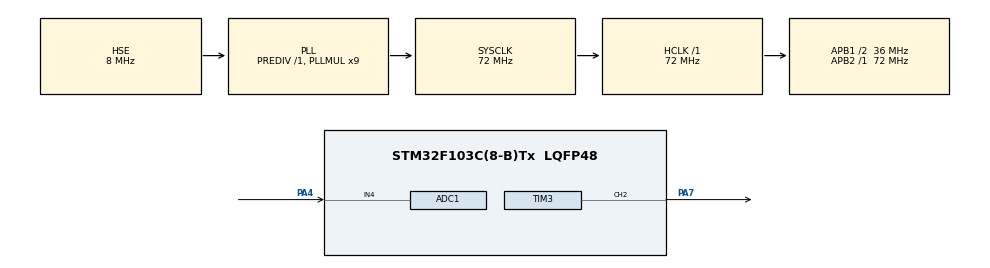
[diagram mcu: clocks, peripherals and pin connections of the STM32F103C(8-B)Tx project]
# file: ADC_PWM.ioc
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ADC1.Channel-0\#ChannelRegularConversion=ADC_CHANNEL_4
ADC1.DiscontinuousConvMode=DISABLE
ADC1.NbrOfConversion=1
ADC1.NbrOfConversionFlag=1
ADC1.Rank-0\#ChannelRegularConversion=1
ADC1.SamplingTime-0\#ChannelRegularConversion=ADC_SAMPLETIME_7CYCLES_5
ADC1.master=1
Mcu.Family=STM32F1
Mcu.Name=STM32F103C(8-B)Tx
Mcu.Package=LQFP48
NVIC.PriorityGroup=NVIC_PRIORITYGROUP_4
PA4.Signal=ADCx_IN4
PA7.Signal=S_TIM3_CH2
PD0-OSC_IN.Mode=HSE-External-Oscillator
PD0-OSC_IN.Signal=RCC_OSC_IN
PD1-OSC_OUT.Mode=HSE-External-Oscillator
PD1-OSC_OUT.Signal=RCC_OSC_OUT
ProjectManager.HeapSize=0x200
ProjectManager.StackSize=0x400
ProjectManager.TargetToolchain=Makefile
RCC.ADCPresc=RCC_ADCPCLK2_DIV6
RCC.AHBFreq_Value=72000000
RCC.APB1CLKDivider=RCC_HCLK_DIV2
RCC.APB1Freq_Value=36000000
RCC.APB1TimFreq_Value=72000000
RCC.APB2Freq_Value=72000000
RCC.APB2TimFreq_Value=72000000
RCC.HCLKFreq_Value=72000000
RCC.PLLMUL=RCC_PLL_MUL9
RCC.PLLSourceVirtual=RCC_PLLSOURCE_HSE
RCC.SYSCLKFreq_VALUE=72000000
RCC.SYSCLKSource=RCC_SYSCLKSOURCE_PLLCLK
RCC.USBFreq_Value=72000000
SH.ADCx_IN4.0=ADC1_IN4,IN4
SH.S_TIM3_CH2.0=TIM3_CH2,PWM Generation2 CH2
TIM3.Channel-PWM\ Generation2\ CH2=TIM_CHANNEL_2
TIM3.Period=2000-1
TIM3.Prescaler=720-1
VP_SYS_VS_ND.Mode=No_Debug
board=custom

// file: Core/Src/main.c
/* USER CODE BEGIN Header */
/**
  ******************************************************************************
  * @file           : main.c
  * @brief          : Main program body
  ******************************************************************************
  * @attention
  *
  * Copyright (c) 2026 STMicroelectronics.
  * All rights reserved.
  *
  * This software is licensed under terms that can be found in the LICENSE file
  * in the root directory of this software component.
  * If no LICENSE file comes with this software, it is provided AS-IS.
  *
  ******************************************************************************
  */
/* USER CODE END Header */
#include "main.h"
#include "adc.h"
#include "tim.h"
#include "gpio.h"

void SystemClock_Config(void);

/* USER CODE BEGIN 0 */
uint16_t adc_x;
uint16_t ccr_val;
/* USER CODE END 0 */

int main(void)
{

  /* MCU Configuration--------------------------------------------------------*/

  /* Reset of all peripherals, Initializes the Flash interface and the Systick. */
  HAL_Init();

  /* Configure the system clock */
  SystemClock_Config();

  /* Initialize all configured peripherals */
  MX_GPIO_Init();
  MX_ADC1_Init();
  MX_TIM3_Init();
  /* USER CODE BEGIN 2 */
HAL_TIM_PWM_Start(&htim3,TIM_CHANNEL_2);
  /* USER CODE END 2 */

  /* Infinite loop */
  while (1)
  {

    /* USER CODE BEGIN 3 */
    if(HAL_ADC_Start(&hadc1)==HAL_OK)
    {
      if(HAL_ADC_PollForConversion(&hadc1,1)==HAL_OK)
      {
        adc_x=HAL_ADC_GetValue(&hadc1);
        ccr_val=50U+(uint16_t)((200UL*adc_x)/4095U);
        __HAL_TIM_SET_COMPARE(&htim3,TIM_CHANNEL_2,ccr_val);
      }
      HAL_ADC_Stop(&hadc1);
    }
    HAL_Delay(20);
  }
  /* USER CODE END 3 */
}

void SystemClock_Config(void)
{
  RCC_OscInitTypeDef RCC_OscInitStruct = {0};
  RCC_ClkInitTypeDef RCC_ClkInitStruct = {0};
  RCC_PeriphCLKInitTypeDef PeriphClkInit = {0};

  /** Initializes the RCC Oscillators according to the specified parameters
  * in the RCC_OscInitTypeDef structure.
  */
  RCC_OscInitStruct.OscillatorType = RCC_OSCILLATORTYPE_HSE;
  RCC_OscInitStruct.HSEState = RCC_HSE_ON;
  RCC_OscInitStruct.HSEPredivValue = RCC_HSE_PREDIV_DIV1;
  RCC_OscInitStruct.HSIState = RCC_HSI_ON;
  RCC_OscInitStruct.PLL.PLLState = RCC_PLL_ON;
  RCC_OscInitStruct.PLL.PLLSource = RCC_PLLSOURCE_HSE;
  RCC_OscInitStruct.PLL.PLLMUL = RCC_PLL_MUL9;
  if (HAL_RCC_OscConfig(&RCC_OscInitStruct) != HAL_OK)
  {
    Error_Handler();
  }

  /** Initializes the CPU, AHB and APB buses clocks
  */
  RCC_ClkInitStruct.ClockType = RCC_CLOCKTYPE_HCLK|RCC_CLOCKTYPE_SYSCLK
                              |RCC_CLOCKTYPE_PCLK1|RCC_CLOCKTYPE_PCLK2;
  RCC_ClkInitStruct.SYSCLKSource = RCC_SYSCLKSOURCE_PLLCLK;
  RCC_ClkInitStruct.AHBCLKDivider = RCC_SYSCLK_DIV1;
  RCC_ClkInitStruct.APB1CLKDivider = RCC_HCLK_DIV2;
  RCC_ClkInitStruct.APB2CLKDivider = RCC_HCLK_DIV1;

  if (HAL_RCC_ClockConfig(&RCC_ClkInitStruct, FLASH_LATENCY_2) != HAL_OK)
  {
    Error_Handler();
  }
  PeriphClkInit.PeriphClockSelection = RCC_PERIPHCLK_ADC;
  PeriphClkInit.AdcClockSelection = RCC_ADCPCLK2_DIV6;
  if (HAL_RCCEx_PeriphCLKConfig(&PeriphClkInit) != HAL_OK)
  {
    Error_Handler();
  }
}

void Error_Handler(void)
{
  __disable_irq();
  while (1)
  {
  }
}
